AUTOSAR XML (schema 4-2-2)
standard types defined: uint16, uint8
package /AUTOSAR/Compositions
  composition sw component type BottomComposition
    component CptReceiverPrototype: type=CptObs
    component CptSenderPrototype: type=CptCtrl
    connect CptSenderPrototype.PpExplict -> CptReceiverPrototype.RpExplicit
  composition sw component type TopComposition
    component BottomComposition: type=BottomComposition
package /AUTOSAR/SwcImplementations
  swc implementation swcImplementation_CptCtrl: behavior=IbCtrl
  swc implementation swcImplementation_CptObs: behavior=IbObs
package /AUTOSAR/System
  system system_0
    system mapping SystemMapping_0
      sw-impl-mappings:
        swc to impl mapping CptSenderPrototypeImplMapping: component-implementation=swcImplementation_CptCtrl, component=rootSwCompositionPrototype_0.BottomComposition.CptSenderPrototype.CptSenderPrototype
        swc to impl mapping CptReceiverPrototypeImplMapping: component-implementation=swcImplementation_CptObs, component=rootSwCompositionPrototype_0.BottomComposition.CptReceiverPrototype.CptReceiverPrototype
      sw-mappings:
        swc to ecu mapping ECUA_SwcToEcuMapping: component=rootSwCompositionPrototype_0.BottomComposition.BottomComposition, ecu-instance=ECUA
    root-software-compositions:
      root sw composition prototype rootSwCompositionPrototype_0: software-composition=TopComposition
package /AUTOSAR/Components
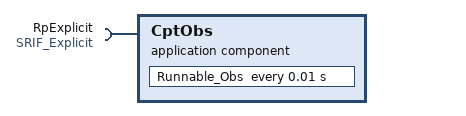
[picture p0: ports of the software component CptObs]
  application sw component type CptObs
    require port RpExplicit: required-interface=SRIF_Explicit
      required-com-specs:
        data-element=dataElementPrimitive, external-replacement=dataElementPrimitive, init-value=0
        data-element=dataElementStruct, init-value=fields=[0, 1, 2]
    behavior IbObs: data-type-mapping=dataTypeMappingSet_U16
      timing event timingEvent_10: start-on-event=Runnable_Obs, period=0.01
      runnable Runnable_Obs: symbol=AppRunnable_Obs
        data-receive-point-by-arguments:
          access DataReceiveByArgPrimitive: accessed-variable=RpExplicit.dataElementPrimitive
          access DataReceiveByArgArray: accessed-variable=RpExplicit.dataElementArray
          access DataReceiveByArgStruct: accessed-variable=RpExplicit.dataElementStruct
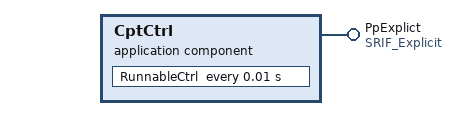
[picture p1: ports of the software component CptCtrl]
  application sw component type CptCtrl
    provide port PpExplict: provided-interface=SRIF_Explicit
    behavior IbCtrl: data-type-mapping=dataTypeMappingSet_U16
      timing event timingEvent_10: start-on-event=RunnableCtrl, period=0.01
      runnable RunnableCtrl: symbol=AppRunnableCtrl
        data-send-points:
          access DataSendPointsPrimitive: accessed-variable=PpExplict.dataElementPrimitive
          access dataSendPointsArray: accessed-variable=PpExplict.dataElementArray
          access dataSendPointsStruct: accessed-variable=PpExplict.dataElementStruct
package /AUTOSAR/DataTypeMappingSets
  data type mapping set dataTypeMappingSet_U16: data-type-map{application-data-type=AdtPrimitiveU16, implementation-data-type=PrimitiveUint16}
package /AUTOSAR/DataTypes
  app type AdtPrimitiveU16: category=VALUE, implementation-data-type=PrimitiveUint16
  impl type PrimitiveUint16: category=VALUE, base-type=uint16
  impl type StructA: category=STRUCTURE
    element Crc_Uint8: category=VALUE, base-type=uint8
    element Data_Uint16: category=VALUE, base-type=uint16
    element Counter_Uint8: category=VALUE, base-type=uint8
  impl type ArrayUint8: category=ARRAY
    element subElement: category=VALUE, array-size=10, base-type=uint8
package /AUTOSAR/Interfaces
  sender receiver interface SRIF_Explicit
    data dataElementPrimitive: type=AdtPrimitiveU16
    data dataElementArray: type=ArrayUint8
    data dataElementStruct: type=StructA
package /AUTOSAR/PortInterfaceMappingSets
  port interface mapping set portInterfaceMappingSet_0
package /SystemInfo/EcuInstances
  ecu instance ECUA: com-configuration-gw-time-base=0.005, com-configuration-rx-time-base=0.005, com-configuration-tx-time-base=0.005, sleep-mode-supported=false, wake-up-over-bus-supported=false
